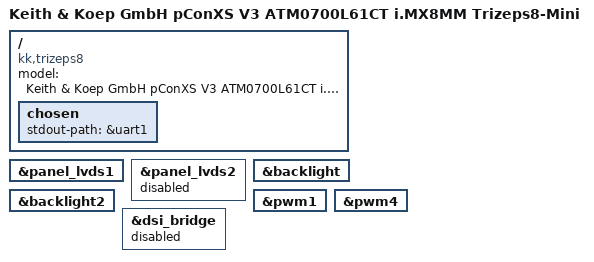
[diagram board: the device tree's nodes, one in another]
/*
 * Copyright 2020 Keith & Koep GmbH
 *
 */

/dts-v1/;

// Add defines here, which control behaviour of .dtsi:

#include "trizeps8plus.dtsi"
#include "dual-espresso-kuk.dtsi"

/ {
	model      = "Keith & Koep GmbH pConXS V3 ATM0700L61CT i.MX8MM Trizeps8-Mini";
	compatible = "kk,trizeps8", "kk,trizeps8mini", "kk,trizeps8plus", "fsl,imx8mp-evk", "fsl,imx8mp";

	chosen {
		stdout-path = &uart1;
	};
};

&panel_lvds1 {
	status = "okay";
};

&panel_lvds2 {
	//status = "okay";
	status = "disabled";
};

&backlight {
	status = "okay";
};

&backlight2 {
	status = "okay";
};

&pwm1 {
	status = "okay";
};

&pwm4 {
	status = "okay";
};

&dsi_bridge {
	//status = "okay";
	status = "disabled";
};
